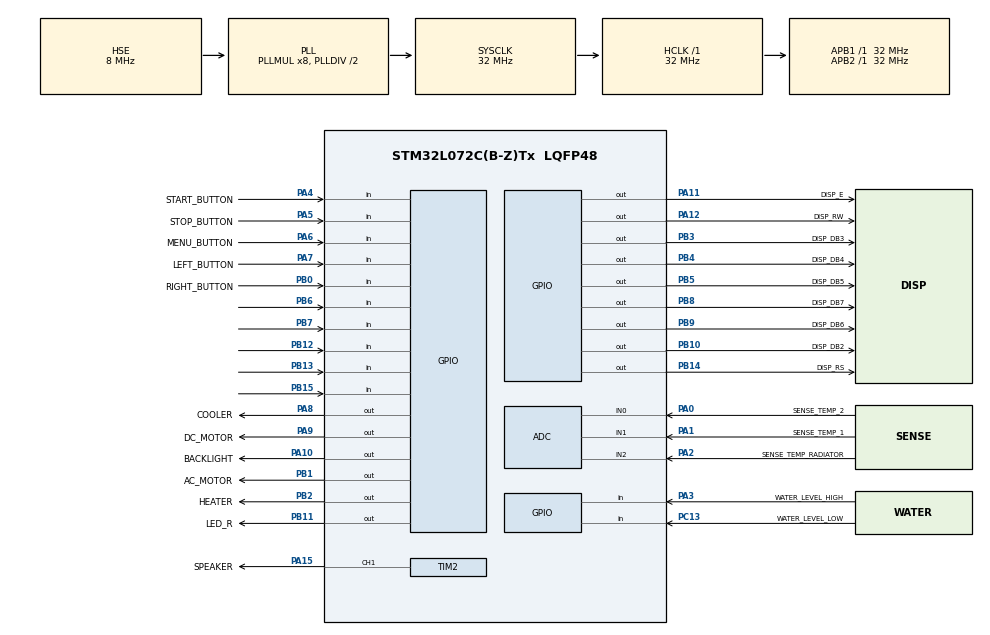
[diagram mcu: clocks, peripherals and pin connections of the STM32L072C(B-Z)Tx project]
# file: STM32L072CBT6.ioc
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ADC.ClockPrescaler=ADC_CLOCK_SYNC_PCLK_DIV4
ADC.EOCSelection=ADC_EOC_SEQ_CONV
ADC.OversamplingMode=DISABLE
ADC.SamplingTime=ADC_SAMPLETIME_12CYCLES_5
Mcu.Family=STM32L0
Mcu.Name=STM32L072C(B-Z)Tx
Mcu.Package=LQFP48
NVIC.ADC1_COMP_IRQn=true\:0\:0\:false\:false\:true\:true\:true
NVIC.RTC_IRQn=true\:0\:0\:false\:false\:true\:true\:true
NVIC.TIM2_IRQn=true\:0\:0\:false\:false\:true\:true\:true
PA0.GPIO_Label=SENSE_TEMP_2
PA0.Mode=IN0
PA0.Signal=ADC_IN0
PA1.GPIO_Label=SENSE_TEMP_1
PA1.Mode=IN1
PA1.Signal=ADC_IN1
PA10.GPIO_Label=BACKLIGHT
PA10.Signal=GPIO_Output
PA11.GPIO_Label=DISP_E
PA11.Signal=GPIO_Output
PA12.GPIO_Label=DISP_RW
PA12.Signal=GPIO_Output
PA13.Mode=Serial_Wire
PA13.Signal=SYS_SWDIO
PA14.Mode=Serial_Wire
PA14.Signal=SYS_SWCLK
PA15.GPIO_Label=SPEAKER
PA15.Signal=S_TIM2_CH1
PA2.GPIO_Label=SENSE_TEMP_RADIATOR
PA2.Mode=IN2
PA2.Signal=ADC_IN2
PA3.GPIO_Label=WATER_LEVEL_HIGH
PA3.Signal=GPIO_Input
PA4.GPIO_Label=START_BUTTON
PA4.Signal=GPIO_Input
PA5.GPIO_Label=STOP_BUTTON
PA5.Signal=GPIO_Input
PA6.GPIO_Label=MENU_BUTTON
PA6.Signal=GPIO_Input
PA7.GPIO_Label=LEFT_BUTTON
PA7.Signal=GPIO_Input
PA8.GPIO_Label=COOLER
PA8.Signal=GPIO_Output
PA9.GPIO_Label=DC_MOTOR
PA9.Signal=GPIO_Output
PB0.GPIO_Label=RIGHT_BUTTON
PB0.Signal=GPIO_Input
PB1.GPIO_Label=AC_MOTOR
PB1.Signal=GPIO_Output
PB10.GPIO_Label=DISP_DB2
PB10.Signal=GPIO_Output
PB11.GPIO_Label=LED_R
PB11.Signal=GPIO_Output
PB12.GPIO_PuPd=GPIO_PULLDOWN
PB12.Signal=GPIO_Input
PB13.GPIO_PuPd=GPIO_PULLDOWN
PB13.Signal=GPIO_Input
PB14.GPIO_Label=DISP_RS
PB14.Signal=GPIO_Output
PB15.Signal=GPIO_Input
PB2.GPIO_Label=HEATER
PB2.Signal=GPIO_Output
PB3.GPIO_Label=DISP_DB3
PB3.Signal=GPIO_Output
PB4.GPIO_Label=DISP_DB4
PB4.Signal=GPIO_Output
PB5.GPIO_Label=DISP_DB5
PB5.Signal=GPIO_Output
PB6.GPIO_PuPd=GPIO_PULLDOWN
PB6.Signal=GPIO_Input
PB7.GPIO_PuPd=GPIO_PULLDOWN
PB7.Signal=GPIO_Input
PB8.GPIO_Label=DISP_DB7
PB8.Signal=GPIO_Output
PB9.GPIO_Label=DISP_DB6
PB9.Signal=GPIO_Output
PC13.GPIO_Label=WATER_LEVEL_LOW
PC13.Signal=GPIO_Input
PC14-OSC32_IN.Mode=LSE-External-Oscillator
PC14-OSC32_IN.Signal=RCC_OSC32_IN
PC15-OSC32_OUT.Mode=LSE-External-Oscillator
PC15-OSC32_OUT.Signal=RCC_OSC32_OUT
PH0-OSC_IN.Mode=HSE-External-Oscillator
PH0-OSC_IN.Signal=RCC_OSC_IN
PH1-OSC_OUT.Mode=HSE-External-Oscillator
PH1-OSC_OUT.Signal=RCC_OSC_OUT
ProjectManager.HeapSize=0x200
ProjectManager.StackSize=0x400
ProjectManager.TargetToolchain=MDK-ARM V5.32
RCC.AHBFreq_Value=32000000
RCC.APB1Freq_Value=32000000
RCC.APB1TimFreq_Value=32000000
RCC.APB2Freq_Value=32000000
RCC.APB2TimFreq_Value=32000000
RCC.EnableCSSLSE=true
RCC.HCLKFreq_Value=32000000
RCC.HSE_VALUE=8000000
RCC.HSI16_VALUE=16000000
RCC.HSI48_VALUE=48000000
RCC.HSI_VALUE=16000000
RCC.MSI_VALUE=2097000
RCC.PLLMUL=RCC_PLLMUL_8
RCC.PLLSourceVirtual=RCC_PLLSOURCE_HSE
RCC.RTCClockSelection=RCC_RTCCLKSOURCE_LSE
RCC.RTCClockSelectionVirtual=RCC_RTCCLKSOURCE_LSE
RCC.SYSCLKFreq_VALUE=32000000
RCC.SYSCLKSource=RCC_SYSCLKSOURCE_PLLCLK
RCC.VCOOutputFreq_Value=64000000
SH.S_TIM2_CH1.0=TIM2_CH1,PWM Generation1 CH1
TIM2.Channel-PWM\ Generation1\ CH1=TIM_CHANNEL_1
VP_ADC_TempSens_Input.Mode=IN-TempSens
VP_ADC_Vref_Input.Mode=IN-Vrefint
VP_RTC_VS_RTC_Activate.Mode=RTC_Enabled
board=custom

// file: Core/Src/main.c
/* USER CODE BEGIN Header */
/**
  ******************************************************************************
  * @file           : main.c
  * @brief          : Main program body
  ******************************************************************************
  * @attention
  *
  * Copyright (c) 2024 STMicroelectronics.
  * All rights reserved.
  *
  * This software is licensed under terms that can be found in the LICENSE file
  * in the root directory of this software component.
  * If no LICENSE file comes with this software, it is provided AS-IS.
  *
  ******************************************************************************
  */
/* USER CODE END Header */
#include "main.h"
#include "adc.h"
#include "rtc.h"
#include "tim.h"
#include "gpio.h"

/* USER CODE BEGIN Includes */
#include "LCD1602.h"
#include "user_interface.h"
#include "temperature_measurement.h"
/* USER CODE END Includes */

void SystemClock_Config(void);

int main(void)
{

  /* MCU Configuration--------------------------------------------------------*/

  /* Reset of all peripherals, Initializes the Flash interface and the Systick. */
  HAL_Init();

  /* USER CODE BEGIN Init */
  HAL_Delay(500);
  /* USER CODE END Init */

  /* Configure the system clock */
  SystemClock_Config();

  /* Initialize all configured peripherals */
  MX_GPIO_Init();
  MX_RTC_Init();
  MX_ADC_Init();
  MX_TIM2_Init();
  /* USER CODE BEGIN 2 */
	//HAL_GPIO_WritePin(DISP_VO_GPIO_Port, DISP_VO_Pin, GPIO_PIN_SET);
	//__HAL_RTC_ALARM_ENABLE_IT(&hrtc, RTC_IT_ALRA);

	TempMeasInit();
	LCD_Init();
	Greeting();

  /* USER CODE END 2 */

  /* Infinite loop */
  /* USER CODE BEGIN WHILE */
  while (1)
  {
		UserInterfaceExecuter();
    /* USER CODE END WHILE */

  }
}

void SystemClock_Config(void)
{
  RCC_OscInitTypeDef RCC_OscInitStruct = {0};
  RCC_ClkInitTypeDef RCC_ClkInitStruct = {0};
  RCC_PeriphCLKInitTypeDef PeriphClkInit = {0};

  /** Configure the main internal regulator output voltage
  */
  __HAL_PWR_VOLTAGESCALING_CONFIG(PWR_REGULATOR_VOLTAGE_SCALE1);
  /** Configure LSE Drive Capability
  */
  HAL_PWR_EnableBkUpAccess();
  __HAL_RCC_LSEDRIVE_CONFIG(RCC_LSEDRIVE_LOW);
  /** Initializes the RCC Oscillators according to the specified parameters
  * in the RCC_OscInitTypeDef structure.
  */
  RCC_OscInitStruct.OscillatorType = RCC_OSCILLATORTYPE_HSE|RCC_OSCILLATORTYPE_LSE;
  RCC_OscInitStruct.HSEState = RCC_HSE_ON;
  RCC_OscInitStruct.LSEState = RCC_LSE_ON;
  RCC_OscInitStruct.PLL.PLLState = RCC_PLL_ON;
  RCC_OscInitStruct.PLL.PLLSource = RCC_PLLSOURCE_HSE;
  RCC_OscInitStruct.PLL.PLLMUL = RCC_PLLMUL_8;
  RCC_OscInitStruct.PLL.PLLDIV = RCC_PLLDIV_2;
  if (HAL_RCC_OscConfig(&RCC_OscInitStruct) != HAL_OK)
  {
    Error_Handler();
  }
  /** Initializes the CPU, AHB and APB buses clocks
  */
  RCC_ClkInitStruct.ClockType = RCC_CLOCKTYPE_HCLK|RCC_CLOCKTYPE_SYSCLK
                              |RCC_CLOCKTYPE_PCLK1|RCC_CLOCKTYPE_PCLK2;
  RCC_ClkInitStruct.SYSCLKSource = RCC_SYSCLKSOURCE_PLLCLK;
  RCC_ClkInitStruct.AHBCLKDivider = RCC_SYSCLK_DIV1;
  RCC_ClkInitStruct.APB1CLKDivider = RCC_HCLK_DIV1;
  RCC_ClkInitStruct.APB2CLKDivider = RCC_HCLK_DIV1;

  if (HAL_RCC_ClockConfig(&RCC_ClkInitStruct, FLASH_LATENCY_1) != HAL_OK)
  {
    Error_Handler();
  }
  PeriphClkInit.PeriphClockSelection = RCC_PERIPHCLK_RTC;
  PeriphClkInit.RTCClockSelection = RCC_RTCCLKSOURCE_LSE;
  if (HAL_RCCEx_PeriphCLKConfig(&PeriphClkInit) != HAL_OK)
  {
    Error_Handler();
  }
  /** Enables the Clock Security System
  */
  HAL_RCCEx_EnableLSECSS();
}

void Error_Handler(void)
{
  __disable_irq();
  while (1)
  {
  }
}
